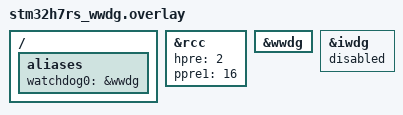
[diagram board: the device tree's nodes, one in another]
/*
 * Copyright (c) 2021 Thomas Stranger
 * Copyright (c) 2022 STMicroelectronics
 *
 * SPDX-License-Identifier: Apache-2.0
 */

/ {
	aliases {
		watchdog0 = &wwdg;
	};
};

&rcc {
	hpre = <2>;
	ppre1 = <16>;
};

&wwdg {
	status = "okay";
};

&iwdg {
	status = "disabled";
};
